# SYS_CTRL register map
Vendor: Texas Instruments
Peripheral module from a debugger description file (folder cc2538).
Registers are 32-bit, access per field, no defined reset value unless marked. A register's access mark holds for its fields unless they carry their own. Offsets are as the file gives them; lines under a group give offsets from that group; [hi:lo] are bit positions; {n}, {i} and the like mark numbered series; 'fields as' and 'values as' point back to an identical list; <NAME> marks a mode.

## SYS_CTRL — Register fields should be considered static unless otherwise noted as dynamic.
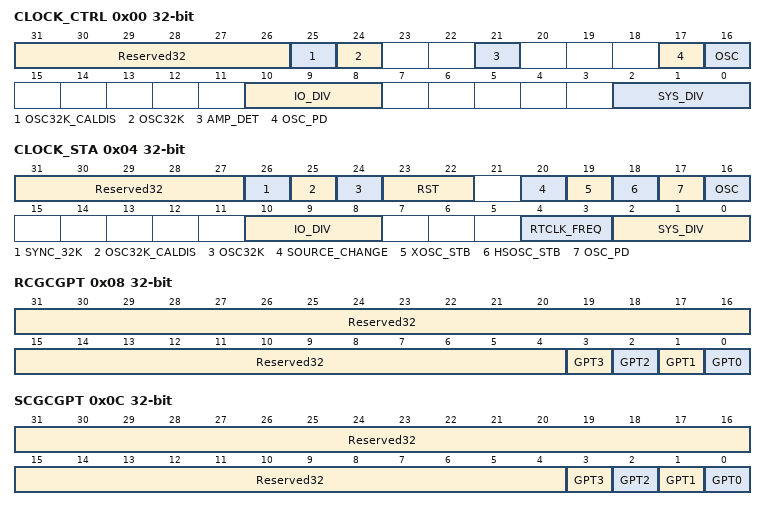
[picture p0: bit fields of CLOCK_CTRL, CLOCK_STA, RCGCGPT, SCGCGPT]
0x00 CLOCK_CTRL — The clock control register handels clock settings in the CC2538. The settings in CLOCK_CTRL do not always reflect the current chip status which is found in CLOCK_STA register.
  [31:26] Reserved32 ro — This register is 8 bits in a 32-bit address space.
  [25] OSC32K_CALDIS rw — Disable calibration 32-kHz RC oscillator. 0: Enable calibration 1: Disable calibration
  [24] OSC32K rw — 32-kHz clock oscillator selection 0: 32-kHz crystal oscillator 1: 32-kHz RC oscillator
  [21] AMP_DET rw — Amplitude detector of XOSC during power up 0: No action 1: Delay qualification of XOSC until amplitude is greater than the threshold.
  [17] OSC_PD rw — 0: Power up both oscillators 1: Power down oscillator not selected by OSC bit (hardware-controlled when selected).
  [16] OSC rw — System clock oscillator selection 0: 32-MHz crystal oscillator 1: 16-MHz HF-RC oscillator
  [10:8] IO_DIV rw — I/O clock rate setting Cannot be higher than OSC setting 000: 32 MHz 001: 16 MHz 010: 8 MHz 011: 4 MHz 100: 2 MHz 101: 1 MHz 110: 0.5 MHz 111: 0.25 MHz
  [2:0] SYS_DIV rw — System clock rate setting Cannot be higher than OSC setting 000: 32 MHz 001: 16 MHz 010: 8 MHz 011: 4 MHz 100: 2 MHz 101: 1 MHz 110: 0.5 MHz 111: 0.25 MHz
0x04 CLOCK_STA ro — Clock status register This register reflects the current chip status.
  [31:27] Reserved32 — This register is 8 bits in a 32-bit address space.
  [26] SYNC_32K — 32-kHz clock source synced to undivided system clock (16 or 32 MHz).
  [25] OSC32K_CALDIS — Disable calibration 32-kHz RC oscillator. 0: Calibration enabled 1: Calibration disabled
  [24] OSC32K — Current 32-kHz clock oscillator selected. 0: 32-kHz crystal oscillator 1: 32-kHz RC oscillator
  [23:22] RST — Returns last source of reset 00: POR 01: External reset 10: WDT 11: CLD or software reset
  [20] SOURCE_CHANGE — 0: System clock is not requested to change. 1: A change of system clock source has been initiated and is not finished. Same as when OSC bit in CLOCK_STA and CLOCK_CTRL register are not equal
  [19] XOSC_STB — XOSC stable status 0: XOSC is not powered up or not yet stable. 1: XOSC is powered up and stable.
  [18] HSOSC_STB — HSOSC stable status 0: HSOSC is not powered up or not yet stable. 1: HSOSC is powered up and stable.
  [17] OSC_PD — 0: Both oscillators powered up and stable and OSC_PD_CMD = 0. 1: Oscillator not selected by CLOCK_CTRL.OSC bit is powered down.
  [16] OSC — Current clock source selected 0: 32-MHz crystal oscillator 1: 16-MHz HF-RC oscillator
  [10:8] IO_DIV — Returns current functional frequency for IO_CLK (may differ from setting in the CLOCK_CTRL register) 000: 32 MHz 001: 16 MHz 010: 8 MHz 011: 4 MHz 100: 2 MHz 101: 1 MHz 110: 0.5 MHz 111: 0.25 MHz
  [4:3] RTCLK_FREQ — Returns current functional frequency for real-time clock. (may differ from setting in the CLOCK_CTRL register) 1x : 8 MHz 01: 2 MHz 00: 62.5 kHz
  [2:0] SYS_DIV — Returns current functional frequency for system clock (may differ from setting in the CLOCK_CTRL register) 000: 32 MHz 001: 16 MHz 010: 8 MHz 011: 4 MHz 100: 2 MHz 101: 1 MHz 110: 0.5 MHz 111: 0.25 MHz
0x08 RCGCGPT — This register defines the module clocks for GPT[3:0] when the CPU is in active (run) mode. This register setting is don't care for PM1-3, because the system clock is powered down in these modes.
  [31:4] Reserved32 ro — This register is 8 bits in a 32-bit address space.
  [n] GPT{n} rw (n=0..3) — 0: Clock for GPT{n} is gated. 1: Clock for GPT{n} is enabled.
0x0C SCGCGPT — This register defines the module clocks for GPT[3:0] when the CPU is in sleep mode. This register setting is don't care for PM1-3, because the system clock is powered down in these modes.
  fields as RCGCGPT
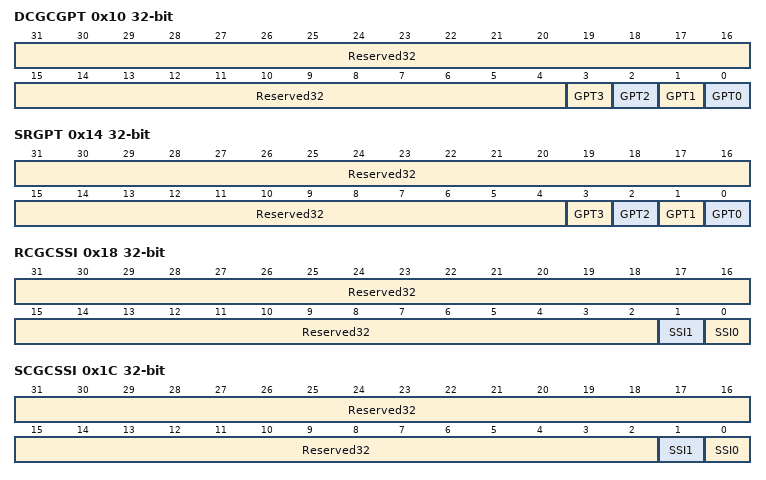
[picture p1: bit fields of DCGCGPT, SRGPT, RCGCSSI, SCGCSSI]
0x10 DCGCGPT — This register defines the module clocks for GPT[3:0] when the CPU is in PM0. This register setting is don't care for PM1-3, because the system clock is powered down in these modes.
  fields as RCGCGPT
0x14 SRGPT — This register controls the reset for GPT[3:0].
  [31:4] Reserved32 ro — This register is 8 bits in a 32-bit address space.
  [n] GPT{n} rw (n=0..3) — 0: GPT{n} module is not reset 1: GPT{n} module is reset
0x18 RCGCSSI — This register defines the module clocks for SSI[1:0] when the CPU is in active (run) mode. This register setting is don't care for PM1-3, because the system clock is powered down in these modes.
  [31:2] Reserved32 ro — This register is 8 bits in a 32-bit address space.
  [1] SSI1 rw — 0: Clock for SSI1 is gated. 1: Clock for SSI1 is enabled.
  [0] SSI0 rw — 0: Clock for SSI0 is gated. 1: Clock for SSI0 is enabled.
0x1C SCGCSSI — This register defines the module clocks for SSI[1:0] when the CPU is insSleep mode. This register setting is don't care for PM1-3, because the system clock is powered down in these modes.
  fields as RCGCSSI
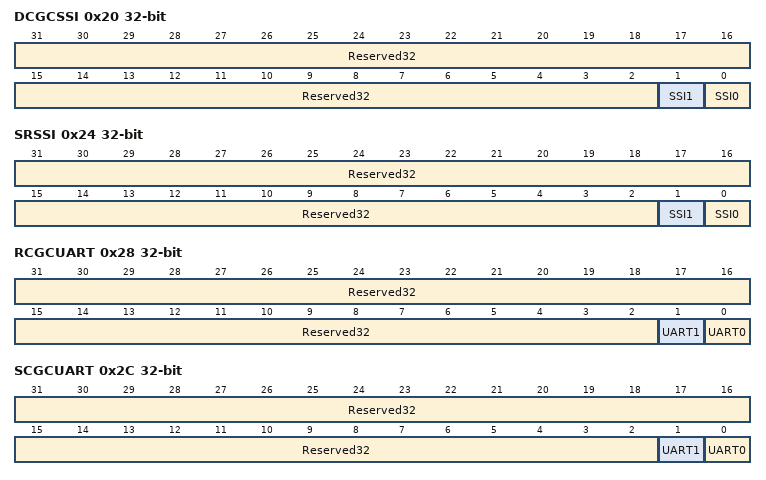
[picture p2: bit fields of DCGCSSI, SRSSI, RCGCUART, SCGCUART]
0x20 DCGCSSI — This register defines the module clocks for SSI[1:0] when the CPU is in PM0. This register setting is don't care for PM1-3, because the system clock is powered down in these modes.
  fields as RCGCSSI
0x24 SRSSI — This register controls the reset for SSI[1:0].
  [31:2] Reserved32 ro — This register is 8 bits in a 32-bit address space.
  [1] SSI1 rw — 0: SSI1 module is not reset 1: SSI1 module is reset
  [0] SSI0 rw — 0: SSI0 module is not reset 1: SSI0 module is reset
0x28 RCGCUART — This register defines the module clocks for UART[1:0] when the CPU is in active (run) mode. This register setting is don't care for PM1-3, because the system clock is powered down in these modes.
  [31:2] Reserved32 ro — This register is 8 bits in a 32-bit address space.
  [1] UART1 rw — 0: Clock for UART1 is gated. 1: Clock for UART1 is enabled.
  [0] UART0 rw — 0: Clock for UART0 is gated. 1: Clock for UART0 is enabled.
0x2C SCGCUART — This register defines the module clocks for UART[1:0] when the CPU is in sleep mode. This register setting is don't care for PM1-3, because the system clock is powered down in these modes.
  fields as RCGCUART
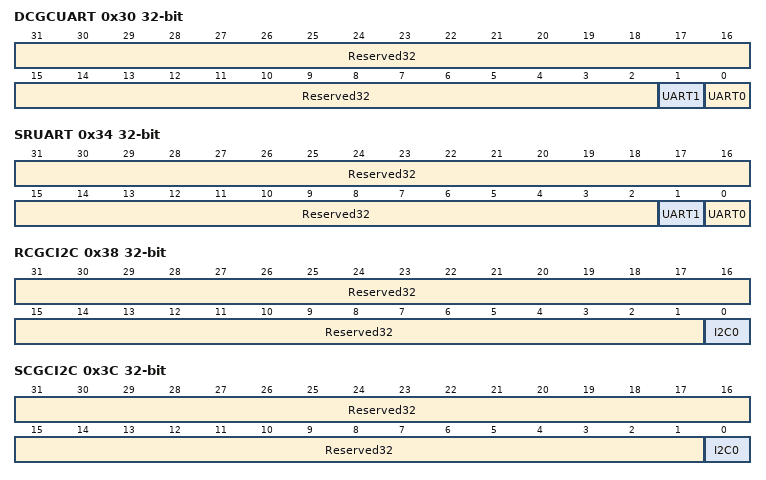
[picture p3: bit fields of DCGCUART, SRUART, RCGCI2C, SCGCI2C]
0x30 DCGCUART — This register defines the module clocks for UART[1:0] when the CPU is in PM0. This register setting is don't care for PM1-3, because the system clock is powered down in these modes.
  fields as RCGCUART
0x34 SRUART — This register controls the reset for UART[1:0].
  [31:2] Reserved32 ro — This register is 8 bits in a 32-bit address space.
  [1] UART1 rw — 0: UART1 module is not reset 1: UART1 module is reset
  [0] UART0 rw — 0: UART0 module is not reset 1: UART0 module is reset
0x38 RCGCI2C — This register defines the module clocks for I2C when the CPU is in active (run) mode. This register setting is don't care for PM1-3, because the system clock is powered down in these modes.
  [31:1] Reserved32 ro — This register is 8 bits in a 32-bit address space.
  [0] I2C0 rw — 0: Clock for I2C0 is gated. 1: Clock for I2C0 is enabled.
0x3C SCGCI2C — This register defines the module clocks for I2C when the CPU is in sleep mode. This register setting is don't care for PM1-3, because the system clock is powered down in these modes.
  fields as RCGCI2C
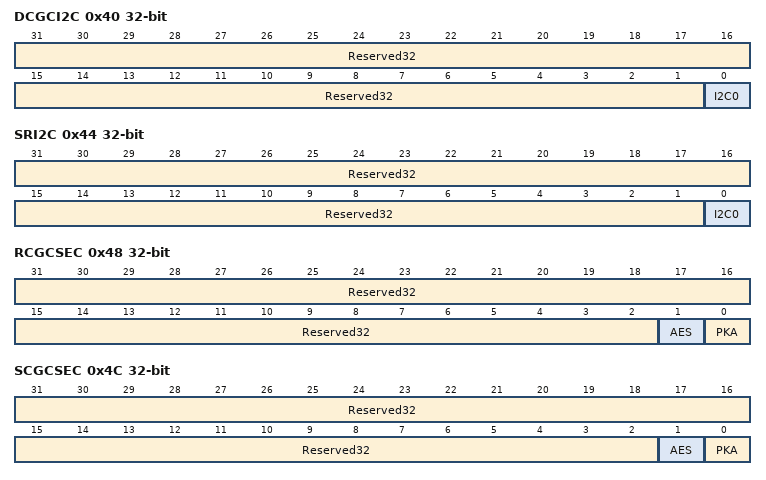
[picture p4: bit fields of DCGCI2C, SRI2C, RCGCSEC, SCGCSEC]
0x40 DCGCI2C — This register defines the module clocks for I2C when the CPU is in PM0. This register setting is don't care for PM1-3, because the system clock is powered down in these modes.
  fields as RCGCI2C
0x44 SRI2C — This register controls the reset for I2C.
  [31:1] Reserved32 ro — This register is 8 bits in a 32-bit address space.
  [0] I2C0 rw — 0: I2C0 module is not reset 1: I2C0 module is reset
0x48 RCGCSEC — This register defines the module clocks for the security module when the CPU is in active (run) mode. This register setting is don't care for PM1-3, because the system clock is powered down in these modes.
  [31:2] Reserved32 ro — This register is 8 bits in a 32-bit address space.
  [1] AES rw — 0: Clock for AES is gated. 1: Clock for AES is enabled.
  [0] PKA rw — 0: Clock for PKA is gated. 1: Clock for PKA is enabled.
0x4C SCGCSEC — This register defines the module clocks for the security module when the CPU is in sleep mode. This register setting is don't care for PM1-3, because the system clock is powered down in these modes.
  fields as RCGCSEC
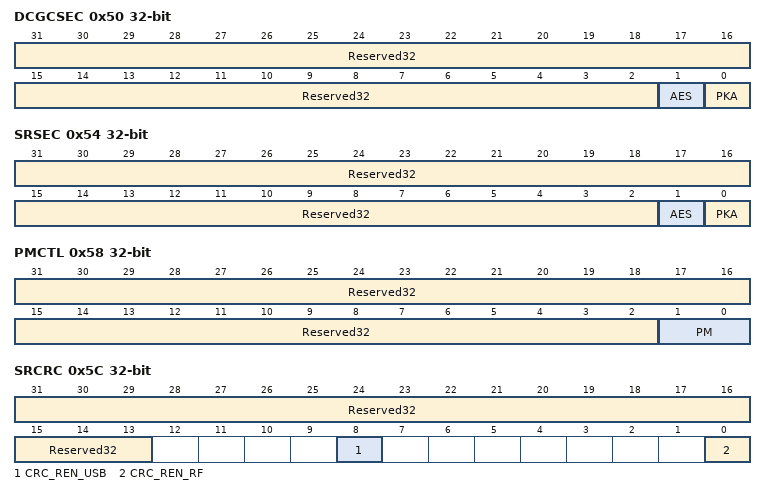
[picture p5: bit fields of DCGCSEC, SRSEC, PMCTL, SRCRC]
0x50 DCGCSEC — This register defines the module clocks for the security module when the CPU is in PM0. This register setting is don't care for PM1-3, because the system clock is powered down in these modes.
  fields as RCGCSEC
0x54 SRSEC — This register controls the reset for the security module.
  [31:2] Reserved32 ro — This register is 8 bits in a 32-bit address space.
  [1] AES rw — 0: AES module is not reset 1: AES module is reset
  [0] PKA rw — 0: PKA module is not reset 1: PKA module is reset
0x58 PMCTL — This register controls the power mode. Note: The Corresponding PM is not entered before the WFI instruction is asserted. To enter PM1-3 the DEEPSLEEP bit in SYSCTRL must be 1.
  [31:2] Reserved32 ro — This register is 8 bits in a 32-bit address space.
  [1:0] PM rw — 00: No action 01: PM1 10: PM2 11: PM3
0x5C SRCRC — This register controls CRC on state retention.
  [31:13] Reserved32 ro — This register is 8 bits in a 32-bit address space.
  [8] CRC_REN_USB rw — 1: Enable reset of chip if CRC fails. 0: Disable reset feature of chip due to CRC.
  [0] CRC_REN_RF rw — 1: Enable reset of chip if CRC fails. 0: Disable reset feature of chip due to CRC.
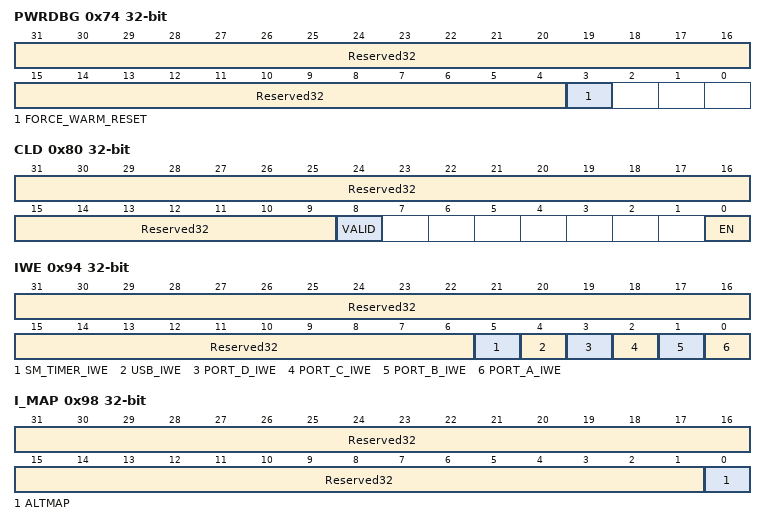
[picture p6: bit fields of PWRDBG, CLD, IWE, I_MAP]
0x74 PWRDBG — Power debug register
  [31:4] Reserved32 ro — This register is 8 bits in a 32-bit address space.
  [3] FORCE_WARM_RESET rw — 0: No action 1: When written high, the chip is reset in the same manner as a CLD event and is readable from the RST field in the CLOCK_STA register.
0x80 CLD — This register controls the clock loss detection feature.
  [31:9] Reserved32 ro — This register is 8 bits in a 32-bit address space.
  [8] VALID ro — 0: CLD status in always-on domain is not equal to status in the EN register. 1: CLD status in always-on domain and EN register are equal.
  [0] EN rw — 0: CLD is disabled. 1: CLD is enabled. Writing to this register shall be ignored if VALID = 0
0x94 IWE — This register controls interrupt wake-up.
  [31:6] Reserved32 ro — This register is 8 bits in a 32-bit address space.
  [5] SM_TIMER_IWE rw — 1: Enable SM Timer wake-up interrupt. 0: Disable SM Timer wake-up interrupt.
  [4] USB_IWE rw — 1: Enable USB wake-up interrupt. 0: Disable USB wake-up interrupt.
  [3] PORT_D_IWE rw — 1: Enable port D wake-up interrupt. 0: Disable port D wake-up interrupt.
  [2] PORT_C_IWE rw — 1: Enable port C wake-up interrupt. 0: Disable port C wake-up interrupt.
  [1] PORT_B_IWE rw — 1: Enable port B wake-up interrupt. 0: Disable port B wake-up interrupt.
  [0] PORT_A_IWE rw — 1: Enable port A wake-up interrupt. 0: Disable port A wake-up interrupt.
0x98 I_MAP — This register selects which interrupt map to be used.
  [31:1] Reserved32 ro — This register is 8 bits in a 32-bit address space.
  [0] ALTMAP rw — 1: Select alternate interrupt map. 0: Select regular interrupt map. (See the ASD document for details.)
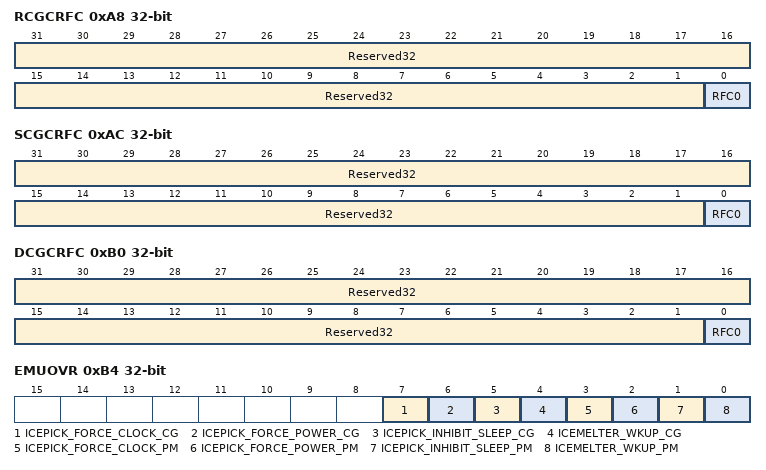
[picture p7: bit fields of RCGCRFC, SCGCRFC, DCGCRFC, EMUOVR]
0xA8 RCGCRFC — This register defines the module clocks for RF CORE when the CPU is in active (run) mode. This register setting is don't care for PM1-3, because the system clock is powered down in these modes.
  [31:1] Reserved32 ro — This register is 8 bits in a 32-bit address space.
  [0] RFC0 rw — 0: Clock for RF CORE is gated. 1: Clock for RF CORE is enabled.
0xAC SCGCRFC — This register defines the module clocks for RF CORE when the CPU is in sleep mode. This register setting is don't care for PM1-3, because the system clock is powered down in these modes.
  fields as RCGCRFC
0xB0 DCGCRFC — This register defines the module clocks for RF CORE when the CPU is in PM0. This register setting is don't care for PM1-3, because the system clock is powered down in these modes.
  fields as RCGCRFC
0xB4 EMUOVR — This register defines the emulator override controls for power mode and peripheral clock gate.
  [7] ICEPICK_FORCE_CLOCK_CG rw — ICEPick 'Force Active' clock gate override bit. 'Force Active' is an ICEPick command. 1 --> In non-sleep power mode, peripherals clocks are forced to follow RCG* register settings. It forces CM3 clocks on. 0 --> Does not affect the peripheral clock settings.
  [6] ICEPICK_FORCE_POWER_CG rw — ICEPick 'Force Power' clock gate override bit. 'Force Power' is an ICEPick command. 1 --> In non-sleep power mode, peripherals clocks are forced to follow RCG* register settings. It forces CM3 clocks on. 0 --> Does not affect the peripheral clock settings.
  [5] ICEPICK_INHIBIT_SLEEP_CG rw — ICEPick 'Inhibit Sleep' clock gate override bit. 'Inhibit Sleep' is an ICEPick command. 1 --> In non-sleep power mode, peripherals clocks are forced to follow RCG* register settings. It forces CM3 clocks on. 0 --> Does not affect the peripheral clock settings.
  [4] ICEMELTER_WKUP_CG rw — ICEMelter 'WAKEUPEMU' clock gate override bit. 1 --> In non-sleep power mode, peripherals clocks are forced to follow RCG* register settings. It forces CM3 clocks on. 0 --> Does not affect the peripheral clock settings
  [3] ICEPICK_FORCE_CLOCK_PM rw — ICEPick 'Force Active' power mode override bit. 'Force Active' is an ICEPick command. 1 --> Prohibit the system to go into any power down modes. Keeps the emulator attached. 0 --> Does not override any power mode settings from SYSREGS and does not prohibit system to go into any power down modes.
  [2] ICEPICK_FORCE_POWER_PM rw — ICEPick 'Force Power' power mode override bit. 'Force Power' is an ICEPick command. 1 --> Prohibit the system to go into any power down modes. Keeps the emulator attached. 0 --> Does not override any power mode settings from SYSREGS and does not prohibit system to go into any power down modes.
  [1] ICEPICK_INHIBIT_SLEEP_PM rw — ICEPick 'Inhibit Sleep' power mode override bit. 'Inhibit Sleep' is an ICEPick command. 1 --> Prohibit the system to go into any power down modes. Keeps the emulator attached. 0 --> Does not override any power mode settings from SYSREGS and does not prohibit system to go into any power down modes.
  [0] ICEMELTER_WKUP_PM rw — ICEMelter 'WAKEUPEMU' power mode override bit. 1 --> Prohibit the system to go into any power down modes. Keeps the emulator attached. 0 --> Does not override any power mode settings from SYSREGS and does not prohibit system to go into any power down modes.
